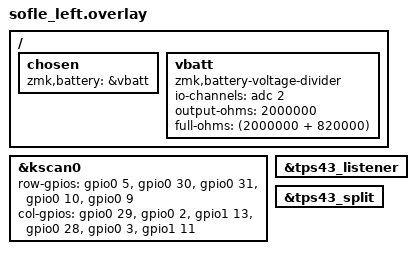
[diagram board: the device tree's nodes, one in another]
/*
 * Copyright (c) 2020 Ryan Cross
 *
 * SPDX-License-Identifier: MIT
 */

#include "sofle.dtsi"

&kscan0 {
    // Schematic nets row0 through row4.
    row-gpios
        = <&gpio0 5 (GPIO_ACTIVE_HIGH | GPIO_PULL_DOWN)>
        , <&gpio0 30 (GPIO_ACTIVE_HIGH | GPIO_PULL_DOWN)>
        , <&gpio0 31 (GPIO_ACTIVE_HIGH | GPIO_PULL_DOWN)>
        , <&gpio0 10 (GPIO_ACTIVE_HIGH | GPIO_PULL_DOWN)>
        , <&gpio0 9 (GPIO_ACTIVE_HIGH | GPIO_PULL_DOWN)>
        ;

    // Schematic nets col0 through col5.
    col-gpios
        = <&gpio0 29 GPIO_ACTIVE_HIGH>
        , <&gpio0 2 GPIO_ACTIVE_HIGH>
        , <&gpio1 13 GPIO_ACTIVE_HIGH>
        , <&gpio0 28 GPIO_ACTIVE_HIGH>
        , <&gpio0 3 GPIO_ACTIVE_HIGH>
        , <&gpio1 11 GPIO_ACTIVE_HIGH>
        ;
};

/ {
    chosen {
      zmk,battery = &vbatt;
    };

    vbatt: vbatt {
        compatible = "zmk,battery-voltage-divider";
        io-channels = <&adc 2>;
        // Schematic: VBAT -- R10 820K -- AIN2 -- R11 2M -- GND.
        output-ohms = <2000000>;
        full-ohms = <(2000000 + 820000)>;
    };
};

&tps43_listener {
    status = "okay";
};

&tps43_split {
    status = "okay";
};
